# STM32MP25_CM33 register map
File version: 1.3
CPU: CM33 r0p1, little endian, MPU, FPU, vendor SysTick, 8 interrupt priority bits
Registers are 32-bit, read-write, reset 0x0 unless marked. A register's access mark holds for its fields unless they carry their own. Offsets are from the block's base; [hi:lo] are bit positions.

## COMBOPHY — COMBOPHY register block
Base 0x480C0000
Same registers: COMBOPHY_S 0x580C0000
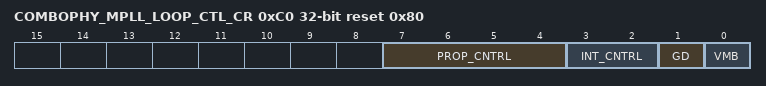
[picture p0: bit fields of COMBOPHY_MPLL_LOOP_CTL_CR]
0xC0 COMBOPHY_MPLL_LOOP_CTL_CR reset 0x80 — COMBOPHY MPLL loop control register
  [7:4] PROP_CNTRL — Charge pump proportional current setting Set PROP_CNTRL to 0xe (0b1110) when the reference clock is 20 or 25MHz. Set PROP_CNTRL to 0x8 (0b1000) when reference clock is 100MHz (default).
  [3:2] INT_CNTRL — Charge pump integrating current setting
  [1] GD — Measure MPLL local GD
  [0] VMB — Measure MPLL master bias voltage

## CRC — CRC address block description
Base 0x404C0000
Same registers: CRC_S 0x504C0000
0x00 CRC_DR reset 0xFFFFFFFF — CRC data register
  [31:0] DR — Data register bits This register is used to write new data to the CRC calculator. It holds the previous CRC calculation result when it is read. If the data size is less than 32 bits, the least significant bits are used to write/read the correct value.
0x04 CRC_IDR — CRC independent data register
  [31:0] IDR — General-purpose 32-bit data register bits These bits can be used as a temporary storage location for four bytes. This register is not affected by CRC resets generated by the RESET bit in the CRC_CR register
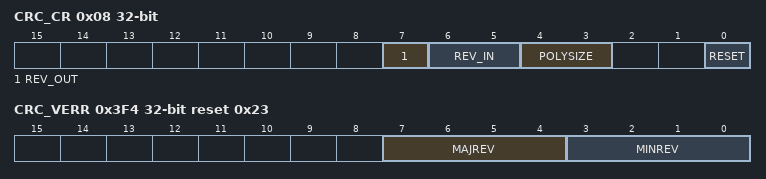
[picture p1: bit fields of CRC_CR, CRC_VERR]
0x08 CRC_CR — CRC control register
  [7] REV_OUT — Reverse output data This bit controls the reversal of the bit order of the output data.
    0=Bit order not affected; 1=Bit-reversed output format
  [6:5] REV_IN — Reverse input data This bit field controls the reversal of the bit order of the input data
    0=Bit order not affected; 1=Bit reversal done by byte; 2=Bit reversal done by half-word; 3=Bit reversal done by word
  [4:3] POLYSIZE — Polynomial size These bits control the size of the polynomial.
    0=32 bit polynomial; 1=16 bit polynomial; 2=8 bit polynomial; 3=7 bit polynomial
  [0] RESET — RESET bit This bit is set by software to reset the CRC calculation unit and set the data register to the value stored in the CRC_INIT register. This bit can only be set, it is automatically cleared by hardware
0x10 CRC_INIT reset 0xFFFFFFFF — CRC initial value
  [31:0] CRC_INIT — Programmable initial CRC value This register is used to write the CRC initial value.
0x14 CRC_POL reset 0x4C11DB7 — CRC polynomial
  [31:0] POL — Programmable polynomial This register is used to write the coefficients of the polynomial to be used for CRC calculation. If the polynomial size is less than 32 bits, the least significant bits have to be used to program the correct value.
0x3F0 CRC_HWCFGR ro (reset mask 0xFFFFFF00) — CRC hardware configuration register
  [7:0] FULL_POLY — Polynomial type Others: Reserved, must not be used.
    0=Fixed polynomial 0x4C11DB7; 1=Programmable polynomial coefficients and size (7,8,16,32)
0x3F4 CRC_VERR ro reset 0x23 — CRC version register
  [7:4] MAJREV — Major revision These bits return the CRC major revision.
  [3:0] MINREV — Minor revision These bits return the CRC minor revision.
0x3F8 CRC_IPIDR ro reset 0x170001 — CRC identification register
  [31:0] ID — Peripheral identifier These bits return the CRC identifier: ID[31:0]=0x0017 0001
0x3FC CRC_SIDR ro reset 0xA3C5DD01 — CRC size identification register
  [31:0] SID — Size identification These bits return the size of the memory region allocated to CRC registers. The size of this memory region is of 1Kbyte: SID[31:0] = 0xA3C5 DD01

## GICV2M — GICV2M register block
Base 0x48090000
Same registers: GICV2M_S 0x58090000
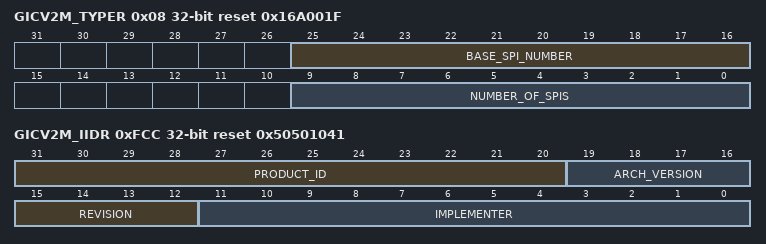
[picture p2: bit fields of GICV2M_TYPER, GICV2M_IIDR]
0x08 GICV2M_TYPER ro reset 0x16A001F
  [25:16] BASE_SPI_NUMBER — Returns the lowest SPI ID assigned to the frame
    0x16A=Dedicated SPI with the ID identified in MSI_SETSPI register is generated
  [9:0] NUMBER_OF_SPIS — Returns the number-1 of contiguous SPIs assigned to the frame.
    31=32 SPI are assigned to the MSI
0x40 GICV2M_SETSPI
  [9:0] SPI1_NUM — On a write, an edge-triggered interrupt is generated to the GIC generic interrupt controller for an SPI with the ID identified by the value of this field. If the resulting value does not identify an SPI that is allocated to this frame then the write has no effect.
0x100 GICV2M_MISC_CTRL
  [1] SPI1_MERGED
    0=Dedicated SPI with the ID identified in MSI_SETSPI register is generated; 1=Merged SPI with ID = BASE_SPI_NUMBER-1, that is ID361, is generated for every valid write in MSI_SETSPI
0xFCC GICV2M_IIDR ro reset 0x50501041
  [31:20] PRODUCT_ID — Product identifier
    0x505=STM32MP25xx dice code
  [19:16] ARCH_VERSION — GICV2M architecture version
    0=GICV2M v0
  [15:12] REVISION — Revision number for the component
    1=First STM32MP25xx GICV2M implementation
  [11:0] IMPLEMENTER — JEP106 code of the company that implements the GICV2M
    65=STMicroelectronics
